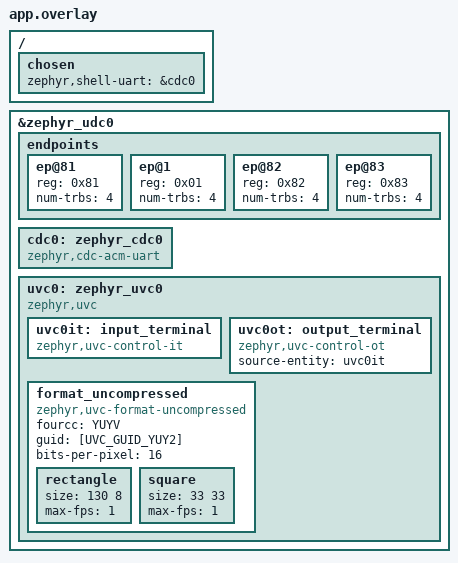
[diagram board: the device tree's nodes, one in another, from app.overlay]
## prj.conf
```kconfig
CONFIG_ASSERT=y
CONFIG_STACK_SENTINEL=y

# Shell
CONFIG_SHELL=y
CONFIG_I2C_SHELL=y
CONFIG_KERNEL_SHELL=y
CONFIG_SHELL_BACKEND_SERIAL_CHECK_DTR=y
CONFIG_SHELL_BACKEND_SERIAL_ASYNC_RX_BUFFER_SIZE=32

# Logging
CONFIG_LOG=y
CONFIG_LOG_MODE_MINIMAL=y
CONFIG_UDC_DRIVER_LOG_LEVEL_DBG=y
CONFIG_USBD_LOG_LEVEL_DBG=y
CONFIG_USBD_UVC_LOG_LEVEL_DBG=y
CONFIG_USBD_CDC_ACM_LOG_LEVEL_WRN=y
CONFIG_VIDEO_LOG_LEVEL_DBG=y

# USB
CONFIG_USBD_CDC_ACM_CLASS=y
CONFIG_USBD_VIDEO_CLASS=y
CONFIG_USBD_VIDEO_HEADER_SIZE=8

# Video
CONFIG_VIDEO=y
CONFIG_VIDEO_BUFFER_POOL_SZ_MAX=2200
CONFIG_VIDEO_BUFFER_POOL_NUM_MAX=1
```

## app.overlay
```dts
/*
 * Copyright (c) 2024 tinyVision.ai Inc.
 * SPDX-License-Identifier: Apache-2.0
 */

#include <zephyr/dt-bindings/usb/video.h>

/ {
	chosen {
		zephyr,shell-uart = &cdc0;
	};
};

&zephyr_udc0 {
	endpoints {
		/* For UVC */
		ep@81 {
			reg = <0x81>;
			num-trbs = <4>;

			/* This example transfers data from RAM: no
			 * uvcmanager = <&...>; here
			 */
		};

		/* For CDC ACM */
		ep@1 {
			reg = <0x01>;
			num-trbs = <4>;
		};
		ep@82 {
			reg = <0x82>;
			num-trbs = <4>;
		};
		ep@83 {
			reg = <0x83>;
			num-trbs = <4>;
		};
	};

	cdc0: zephyr_cdc0 {
		compatible = "zephyr,cdc-acm-uart";
	};

	uvc0: zephyr_uvc0 {
		compatible = "zephyr,uvc";

		uvc0it: input_terminal {
			compatible = "zephyr,uvc-control-it";
		};
		uvc0ot: output_terminal {
			compatible = "zephyr,uvc-control-ot";
			source-entity = <&uvc0it>;
		};

		format_uncompressed {
			compatible = "zephyr,uvc-format-uncompressed";
			fourcc = "YUYV";
			guid = [UVC_GUID_YUY2];
			bits-per-pixel = <16>;

			rectangle {
				size = <130 8>;
				max-fps = <1>;
			};

			square {
				size = <33 33>;
				max-fps = <1>;
			};
		};
	};
};
```

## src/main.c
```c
#include <stdlib.h>

#include <zephyr/kernel.h>
#include <zephyr/devicetree.h>
#include <zephyr/drivers/video.h>
#include <zephyr/shell/shell.h>
#include <zephyr/logging/log.h>

LOG_MODULE_REGISTER(app, LOG_LEVEL_DBG);

const struct device *const uvc0_dev = DEVICE_DT_GET(DT_NODELABEL(uvc0));

int main(void)
{
	int ret;

	ret = video_stream_start(uvc0_dev);
	if (ret) {
		LOG_DBG("could not start UVC device");
		return ret;
	}

	k_sleep(K_FOREVER);
	return 0;
}

/*
 * Send a single video frame whenever hitting the "video frame" command on the shell.
 * This permits to open a video feed with a webcam viewer tool such as VLC, and manually
 * step through every frame.
 *
 * If wanting a continuous video feed instead, repeat this function in loop, eventually
 * only the enqueue()/dequeue() part for efficiency, and possibly with several buffers
 * as done in the video Zephyr samples.
 */
static int cmd_video_frame(const struct shell *sh, size_t argc, char **argv)
{
	struct video_buffer *vbuf;
	struct video_format fmt = {0};
	static uint8_t toggle = 0x00;
	int ret;

	ret = video_get_format(uvc0_dev, VIDEO_EP_IN, &fmt);
	if (ret != 0) {
		shell_error(sh, "could not allocate the video buffer");
		return ret;
	}

	shell_print(sh, "Preparing a %ux%u frame, %u bytes",
		    fmt.pitch, fmt.height, fmt.pitch * fmt.height);

	/* If this gets stuck, you might need to increase CONFIG_VIDEO_BUFFER_POOL_SZ_MAX */
	vbuf = video_buffer_alloc(fmt.pitch * fmt.height);
	if (vbuf == NULL) {
		shell_error(sh, "could not allocate the video buffer");
		return -ENOMEM;
	}

	for (size_t i = 0; i < vbuf->size; i++) {
		vbuf->buffer[i] = i ^ toggle;
	}
	vbuf->bytesused = vbuf->size;
	vbuf->flags = VIDEO_BUF_EOF;

	ret = video_enqueue(uvc0_dev, VIDEO_EP_IN, vbuf);
	if (ret != 0) {
		shell_error(sh, "could not enqueue video buffer");
		goto end;
	}

	ret = video_dequeue(uvc0_dev, VIDEO_EP_IN, &vbuf, K_FOREVER);
	if (ret != 0) {
		shell_error(sh, "could not dequeue video buffer");
		goto end;
	}
	toggle ^= 0xff;
end:
	video_buffer_release(vbuf);
	return ret;
}

SHELL_STATIC_SUBCMD_SET_CREATE(sub_video,
                               SHELL_CMD(frame, NULL, "submit a frame of specified color",
                                         &cmd_video_frame),
                               SHELL_SUBCMD_SET_END);
SHELL_CMD_REGISTER(video, &sub_video, "Video controls", NULL);
```

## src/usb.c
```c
#include <zephyr/drivers/usb/udc.h>
#include <zephyr/usb/usbd.h>
#include <zephyr/usb/bos.h>
#include <zephyr/logging/log.h>

LOG_MODULE_REGISTER(app_usb, LOG_LEVEL_DBG);

static const struct device *const udc0_dev = DEVICE_DT_GET(DT_NODELABEL(zephyr_udc0));

USBD_DEVICE_DEFINE(usbd, udc0_dev, 0x1209, 0x0001);

USBD_DESC_MANUFACTURER_DEFINE(usbd_manufacturer, "tinyVision.ai");
USBD_DESC_PRODUCT_DEFINE(usbd_product, "tinyCLUNX33");
USBD_DESC_LANG_DEFINE(usbd_lang);

static const struct usb_bos_capability_superspeed_usb bos_cap_ss = {
	.bLength = sizeof(struct usb_bos_capability_superspeed_usb),
	.bDescriptorType = USB_DESC_DEVICE_CAPABILITY,
	.bDevCapabilityType = USB_BOS_CAPABILITY_SUPERSPEED_USB,
	.bmAttributes = 0,
	.wSpeedsSupported = sys_cpu_to_le16(USB_BOS_SPEED_SUPERSPEED_GEN1 |
					    USB_BOS_SPEED_HIGHSPEED | USB_BOS_SPEED_FULLSPEED),
	.bFunctionnalSupport = 1,
	.bU1DevExitLat = 10,
	.wU2DevExitLat = sys_cpu_to_le16(1023),
};
USBD_DESC_BOS_DEFINE(usbd_bos_cap_ss, sizeof(bos_cap_ss), &bos_cap_ss);

static const struct usb_bos_capability_lpm bos_cap_lpm = {
	.bLength = sizeof(struct usb_bos_capability_lpm),
	.bDescriptorType = USB_DESC_DEVICE_CAPABILITY,
	.bDevCapabilityType = USB_BOS_CAPABILITY_EXTENSION,
	.bmAttributes = USB_BOS_ATTRIBUTES_LPM,
};
USBD_DESC_BOS_DEFINE(usbd_bos_cap_lpm, sizeof(bos_cap_lpm), &bos_cap_lpm);

USBD_CONFIGURATION_DEFINE(usbd_config_fs, USB_SCD_SELF_POWERED, 100);
USBD_CONFIGURATION_DEFINE(usbd_config_hs, USB_SCD_SELF_POWERED, 100);
USBD_CONFIGURATION_DEFINE(usbd_config_ss, USB_SCD_SELF_POWERED, 100);

int app_usb_init(void)
{
	int err;

	LOG_DBG("Adding USB descriptors");
	err = usbd_add_descriptor(&usbd, &usbd_lang);
	if (err) {
		LOG_ERR("failed to add lang descriptor");
		return err;
	}
	err = usbd_add_descriptor(&usbd, &usbd_manufacturer);
	if (err) {
		LOG_ERR("failed to add manufacturer descriptor");
		return err;
	}
	err = usbd_add_descriptor(&usbd, &usbd_product);
	if (err) {
		LOG_ERR("failed to add product descriptor");
		return err;
	}
	err = usbd_add_descriptor(&usbd, &usbd_bos_cap_lpm);
	if (err) {
		LOG_ERR("failed to add bos_cap_lpm descriptor");
		return err;
	}
	err = usbd_add_descriptor(&usbd, &usbd_bos_cap_ss);
	if (err) {
		LOG_ERR("failed to add bos_cap_ss descriptor");
		return err;
	}

	LOG_DBG("Adding USB configuration");
	err = usbd_add_configuration(&usbd, USBD_SPEED_FS, &usbd_config_fs);
	if (err) {
		LOG_ERR("failed to add FullSpeed, configuration");
		return err;
	}
	err = usbd_add_configuration(&usbd, USBD_SPEED_HS, &usbd_config_hs);
	if (err) {
		LOG_ERR("failed to add HighSpeed, configuration");
		return err;
	}
	err = usbd_add_configuration(&usbd, USBD_SPEED_SS, &usbd_config_ss);
	if (err) {
		LOG_ERR("failed to add SuperSpeed, configuration");
		return err;
	}

	usbd_device_set_code_triple(&usbd, USBD_SPEED_FS, USB_BCC_MISCELLANEOUS, 0x02, 0x01);
	usbd_device_set_code_triple(&usbd, USBD_SPEED_HS, USB_BCC_MISCELLANEOUS, 0x02, 0x01);
	usbd_device_set_code_triple(&usbd, USBD_SPEED_SS, USB_BCC_MISCELLANEOUS, 0x02, 0x01);

	LOG_DBG("Adding USB classes");
	err = usbd_register_all_classes(&usbd, USBD_SPEED_FS, 1);
	if (err) {
		LOG_ERR("failed to register FullSpeed USB clases");
		return err;
	}
	err = usbd_register_all_classes(&usbd, USBD_SPEED_HS, 1);
	if (err) {
		LOG_ERR("failed to register HighSpeed USB clases");
		return err;
	}
	err = usbd_register_all_classes(&usbd, USBD_SPEED_SS, 1);
	if (err) {
		LOG_ERR("failed to register SuperSpeed USB clases");
		return err;
	}

	LOG_DBG("Finalize USB configuration");
	err = usbd_init(&usbd);
	if (err) {
		LOG_ERR("failed to initialize USB");
		return err;
	}

	LOG_DBG("Starting USB operation");
	err = usbd_enable(&usbd);
	if (err) {
		LOG_ERR("failed to enable the USB device");
		return err;
	}

	return 0;
}

SYS_INIT(app_usb_init, APPLICATION, CONFIG_APPLICATION_INIT_PRIORITY);
```
